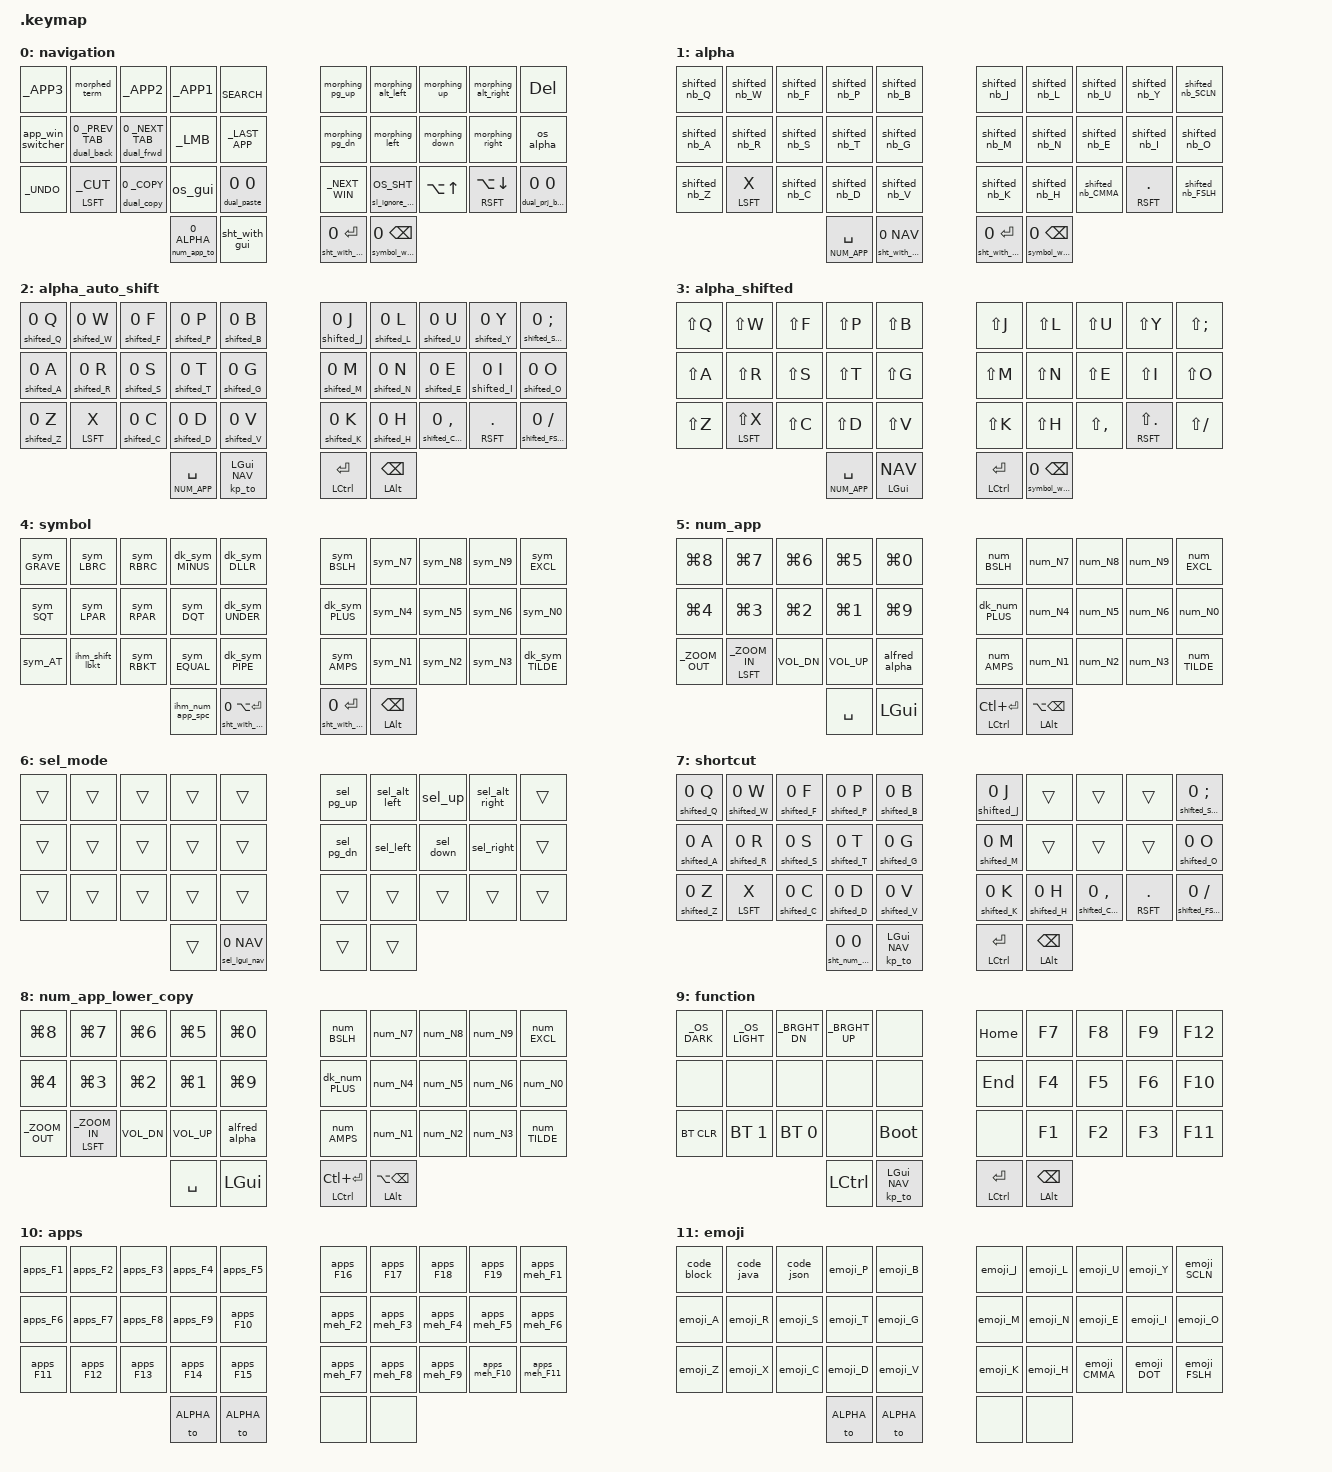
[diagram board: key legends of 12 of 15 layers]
#include <behaviors.dtsi>
#include <dt-bindings/zmk/keys.h>
#include <dt-bindings/zmk/bt.h>
#include "keys.h"

#define NAV                     0
#define ALPHA                   1
#define ALPHA_AUTO_SHIFTED      2
#define ALPHA_SHIFTED           3
#define SYMBOL                  4
#define NUM_APP                 5
#define SEL_MODE                6
#define SHORTCUT                7
#define NUM_APP_LOWER_COPY      8
#define FUNCTION                9
#define APPS                    10
#define EMOJI                   11
#define PASTE_MO                12
#define OS_SHT                  13
#define OS_GUI                  14

&caps_word { continue-list = <UNDERSCORE MINUS BACKSPACE LALT>; };
&sl { release-after-ms = <2000>; };

/ {
conditional_layers {
    compatible = "zmk,conditional-layers";
    tri_layer {
        if-layers = <SHORTCUT NUM_APP>;
        then-layer = <NUM_APP_LOWER_COPY>;
    };
};


combos {
    #include "combos.dtsi"
};

behaviors {
    #include "building_blocks.dtsi"

    #include "behaviors.dtsi"

    #include "macros/auto_shift.dtsi"
    #include "macros/auto_shift_non_breaking.dtsi"
    #include "macros/emoji_layer.dtsi"
    #include "macros/general.dtsi"
    #include "macros/morphed_keys.dtsi"
    #include "macros/num_app_layer.dtsi"
    #include "macros/open_application_layer.dtsi"
    #include "macros/os_sht.dtsi"
    #include "macros/os_gui.dtsi"
    #include "macros/selection_mode.dtsi"
    #include "macros/symbol_layer.dtsi"
};

keymap { compatible = "zmk,keymap";

navigation { bindings = <
    &kp _APP3         &morphed_term          &kp _APP2              &kp _APP1 &kp _SEARCH            &morphing_pg_up &morphing_alt_left          &morphing_up   &morphing_alt_right &kp DEL
    &app_win_switcher &dual_back 0 _PREV_TAB &dual_frwd 0 _NEXT_TAB &kp _LMB  &kp _LAST_APP          &morphing_pg_dn   &morphing_left              &morphing_down &morphing_right     &os_alpha
    &kp _UNDO         &hm LSFT _CUT          &dual_copy 0 _COPY     &os_gui   &dual_paste 0 0        &kp _NEXT_WIN     &sl_ignore_mods_long OS_SHT &kp LA(UP)     &hm RSFT LA(DOWN)   &dual_prj_bkmrks 0 0
                                                            &num_app_to 0 ALPHA &sht_with_gui        &sht_with_ctl_kp 0 RET  &symbol_with_alt_kp 0 BSPC
>;};

alpha { bindings = <
    &shifted_nb_Q &shifted_nb_W &shifted_nb_F &shifted_nb_P &shifted_nb_B        &shifted_nb_J &shifted_nb_L &shifted_nb_U    &shifted_nb_Y &shifted_nb_SCLN
    &shifted_nb_A &shifted_nb_R &shifted_nb_S &shifted_nb_T &shifted_nb_G        &shifted_nb_M &shifted_nb_N &shifted_nb_E    &shifted_nb_I &shifted_nb_O
    &shifted_nb_Z &hm LSFT X    &shifted_nb_C &shifted_nb_D &shifted_nb_V        &shifted_nb_K &shifted_nb_H &shifted_nb_CMMA &hm RSFT DOT  &shifted_nb_FSLH
                                &hm_to NUM_APP SPC &sht_with_gui_to 0 NAV        &sht_with_ctl_kp 0 RET &symbol_with_alt_kp 0 BSPC
>;};

alpha_auto_shift { bindings = <
    &shifted_Q 0 Q &shifted_W 0 W &shifted_F 0 F &shifted_P 0 P &shifted_B 0 B        &shifted_J 0 J &shifted_L 0 L &shifted_U 0 U       &shifted_Y 0 Y &shifted_SCLN 0 SCLN
    &shifted_A 0 A &shifted_R 0 R &shifted_S 0 S &shifted_T 0 T &shifted_G 0 G        &shifted_M 0 M &shifted_N 0 N &shifted_E 0 E       &shifted_I 0 I &shifted_O 0 O
    &shifted_Z 0 Z &hm LSFT X     &shifted_C 0 C &shifted_D 0 D &shifted_V 0 V        &shifted_K 0 K &shifted_H 0 H &shifted_CMMA 0 CMMA &hm RSFT DOT   &shifted_FSLH 0 FSLH
                                            &hm_to NUM_APP SPC &kp_to LGUI NAV        &hm_spc LCTL RET &hm_spc LALT BSPC
>;};

alpha_shifted { bindings = <
    &kp LS(Q) &kp LS(W)      &kp LS(F) &kp LS(P) &kp LS(B)        &kp LS(J) &kp LS(L) &kp LS(U)    &kp LS(Y)        &kp LS(SCLN)
    &kp LS(A) &kp LS(R)      &kp LS(S) &kp LS(T) &kp LS(G)        &kp LS(M) &kp LS(N) &kp LS(E)    &kp LS(I)        &kp LS(O)
    &kp LS(Z) &hm LSFT LS(X) &kp LS(C) &kp LS(D) &kp LS(V)        &kp LS(K) &kp LS(H) &kp LS(CMMA) &hm RSFT LS(DOT) &kp LS(FSLH)
                        &hm_to NUM_APP SPC &hm_to LGUI NAV        &hm_spc LCTL RET &symbol_with_alt_kp 0 BSPC
>;};

symbol { bindings = <
    &sym_GRAVE &sym_LBRC       &sym_RBRC &dk_sym_MINUS &dk_sym_DLLR         &sym_BSLH    &sym_N7 &sym_N8 &sym_N9 &sym_EXCL
    &sym_SQT   &sym_LPAR       &sym_RPAR &sym_DQT      &dk_sym_UNDER        &dk_sym_PLUS &sym_N4 &sym_N5 &sym_N6 &sym_N0
    &sym_AT    &ihm_shift_lbkt &sym_RBKT &sym_EQUAL    &dk_sym_PIPE         &sym_AMPS    &sym_N1 &sym_N2 &sym_N3 &dk_sym_TILDE
                         &ihm_num_app_spc &sht_with_gui_kp 0 LA(RET)        &sht_with_ctl_kp 0 RET &mt LALT BSPC
>;};

num_app { bindings = <
    &kp LG(N8)    &kp LG(N7)        &kp LG(N6)   &kp LG(N5)   &kp LG(N0)           &num_BSLH    &num_N7 &num_N8 &num_N9 &num_EXCL
    &kp LG(N4)    &kp LG(N3)        &kp LG(N2)   &kp LG(N1)   &kp LG(N9)           &dk_num_PLUS &num_N4 &num_N5 &num_N6 &num_N0
    &kp _ZOOM_OUT &hm LSFT _ZOOM_IN &kp C_VOL_DN &kp C_VOL_UP &alfred_alpha        &num_AMPS    &num_N1 &num_N2 &num_N3 &num_TILDE
                                                           &kp SPC &kp LGUI        &mt LCTL LC(RET) &mt LALT LA(BSPC)
>;};

sel_mode { bindings = <
    &trans &trans &trans &trans &trans       &sel_pg_up &sel_alt_left &sel_up   &sel_alt_right &trans
    &trans &trans &trans &trans &trans       &sel_pg_dn &sel_left     &sel_down &sel_right     &trans
    &trans &trans &trans &trans &trans       &trans     &trans        &trans    &trans         &trans
            &trans &sel_lgui_nav 0 NAV       &trans     &trans
>;};

shortcut { bindings = <
    &shifted_Q 0 Q &shifted_W 0 W &shifted_F 0 F &shifted_P 0 P &shifted_B 0 B        &shifted_J 0 J &trans         &trans               &trans       &shifted_SCLN 0 SCLN
    &shifted_A 0 A &shifted_R 0 R &shifted_S 0 S &shifted_T 0 T &shifted_G 0 G        &shifted_M 0 M &trans         &trans               &trans       &shifted_O 0 O
    &shifted_Z 0 Z &hm LSFT X     &shifted_C 0 C &shifted_D 0 D &shifted_V 0 V        &shifted_K 0 K &shifted_H 0 H &shifted_CMMA 0 CMMA &hm RSFT DOT &shifted_FSLH 0 FSLH
                                          &sht_num_app_spc 0 0 &kp_to LGUI NAV        &hm_spc LCTL RET &hm_spc LALT BSPC
>;};

num_app_lower_copy { bindings = <
    &kp LG(N8)    &kp LG(N7)        &kp LG(N6)   &kp LG(N5)   &kp LG(N0)           &num_BSLH    &num_N7 &num_N8 &num_N9 &num_EXCL
    &kp LG(N4)    &kp LG(N3)        &kp LG(N2)   &kp LG(N1)   &kp LG(N9)           &dk_num_PLUS &num_N4 &num_N5 &num_N6 &num_N0
    &kp _ZOOM_OUT &hm LSFT _ZOOM_IN &kp C_VOL_DN &kp C_VOL_UP &alfred_alpha        &num_AMPS    &num_N1 &num_N2 &num_N3 &num_TILDE
                                                           &kp SPC &kp LGUI        &mt LCTL LC(RET) &mt LALT LA(BSPC)
>;};

function { bindings = <
    &kp _OS_DARK &kp _OS_LIGHT &kp _BRGHT_DN &kp _BRGHT_UP &none              &kp HOME &kp F7 &kp F8 &kp F9 &kp F12
    &none        &none         &none         &none         &none              &kp END  &kp F4 &kp F5 &kp F6 &kp F10
    &bt BT_CLR &bt BT_SEL 1    &bt BT_SEL 0  &none         &bootloader        &none    &kp F1 &kp F2 &kp F3 &kp F11
                               &kp LCTL &kp_to LGUI NAV                       &mt LCTL RET &mt LALT BSPC
>;};

apps { bindings = <
    &apps_F1  &apps_F2  &apps_F3  &apps_F4  &apps_F5         &apps_F16    &apps_F17    &apps_F18    &apps_F19     &apps_meh_F1
    &apps_F6  &apps_F7  &apps_F8  &apps_F9  &apps_F10        &apps_meh_F2 &apps_meh_F3 &apps_meh_F4 &apps_meh_F5  &apps_meh_F6
    &apps_F11 &apps_F12 &apps_F13 &apps_F14 &apps_F15        &apps_meh_F7 &apps_meh_F8 &apps_meh_F9 &apps_meh_F10 &apps_meh_F11
                                  &to ALPHA &to ALPHA        &none &none
>;};

emoji { bindings = <
    &code_block &code_java &code_json &emoji_P &emoji_B        &emoji_J &emoji_L &emoji_U    &emoji_Y   &emoji_SCLN
    &emoji_A    &emoji_R   &emoji_S   &emoji_T &emoji_G        &emoji_M &emoji_N &emoji_E    &emoji_I   &emoji_O
    &emoji_Z    &emoji_X   &emoji_C   &emoji_D &emoji_V        &emoji_K &emoji_H &emoji_CMMA &emoji_DOT &emoji_FSLH
                                    &to ALPHA &to ALPHA        &none &none
>;};

paste_mo { bindings = <
    &trans &trans &trans &trans &trans        &trans &trans &trans &trans &trans
    &trans &trans &trans &trans &trans        &trans &trans &trans &trans &trans
    &trans &trans &trans &trans &kp RET       &trans &trans &trans &trans &trans
                         &trans &trans        &trans &trans
>;};

os_sht { bindings = <
    &os_sht_Q &os_sht_W &os_sht_F &os_sht_P &os_sht_B        &os_sht_J &os_sht_L &os_sht_U    &os_sht_Y   &os_sht_SCLN
    &os_sht_A &os_sht_R &os_sht_S &os_sht_T &os_sht_G        &os_sht_M &os_sht_N &os_sht_E    &os_sht_I   &os_sht_O
    &os_sht_Z &os_sht_X &os_sht_C &os_sht_D &os_sht_V        &os_sht_K &os_sht_H &os_sht_CMMA &os_sht_DOT &os_sht_FSLH
                            &os_sht_LBKT &os_sht_RBKT        &os_sht_SQT &os_sht_BSLH

>;};

os_gui { bindings = <
    &shifted_gui_Q 0 LG(Q) &shifted_gui_W 0 LG(W) &shifted_gui_F 0 0     &shifted_gui_P 0 LG(P) &shifted_gui_B 0 LG(B)        &shifted_gui_J 0 LG(J) &shifted_gui_L 0 LG(L) &shifted_gui_U 0 LG(U)       &shifted_gui_Y 0 LG(Y)     &shifted_gui_SCLN 0 LG(SCLN)
    &shifted_gui_A 0 LG(A) &shifted_gui_R 0 LG(R) &shifted_gui_S 0 LG(S) &shifted_gui_T 0 LG(T) &shifted_gui_G 0 LG(G)        &shifted_gui_M 0 LG(M) &shifted_gui_N 0 LG(N) &shifted_gui_E 0 LG(E)       &shifted_gui_I 0 LG(I)     &shifted_gui_O 0 LG(O)
    &shifted_gui_Z 0 LG(Z) &shifted_gui_X 0 LG(X) &shifted_gui_C 0 LG(C) &shifted_gui_D 0 LG(D) &shifted_gui_V 0 LG(V)        &shifted_gui_K 0 LG(K) &shifted_gui_H 0 LG(H) &shifted_gui_CMMA 0 LG(CMMA) &shifted_gui_DOT 0 LG(DOT) &shifted_gui_FSLH 0 LG(FSLH)
                                                                                &hm_to NUM_APP LG(SPC) &kp_to LGUI NAV        &hm_spc LCTL LG(RET) &hm_spc LALT LG(BSPC)
>;};
	};
};
